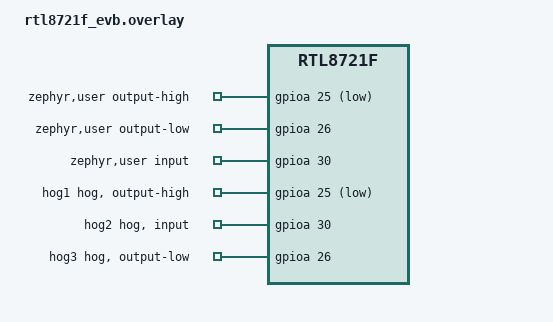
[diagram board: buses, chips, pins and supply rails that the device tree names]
/*
 * Copyright (c) 2024 Realtek Semiconductor Corp.
 *
 * SPDX-License-Identifier: Apache-2.0
 */

#include <zephyr/dt-bindings/gpio/gpio.h>

/ {
	zephyr,user {
		output-high-gpios = <&gpioa 25 GPIO_ACTIVE_LOW>;
		output-low-gpios = <&gpioa 26 GPIO_ACTIVE_HIGH>;
		input-gpios = <&gpioa 30 GPIO_ACTIVE_HIGH>;
	};
};

&gpioa {
	hog1 {
		gpio-hog;
		gpios = <25 GPIO_ACTIVE_LOW>;
		output-high;
	};

	hog2 {
		gpio-hog;
		gpios = <30 GPIO_ACTIVE_HIGH>;
		input;
	};

	hog3 {
		gpio-hog;
		gpios = <26 GPIO_ACTIVE_HIGH>;
		output-low;
	};
};
